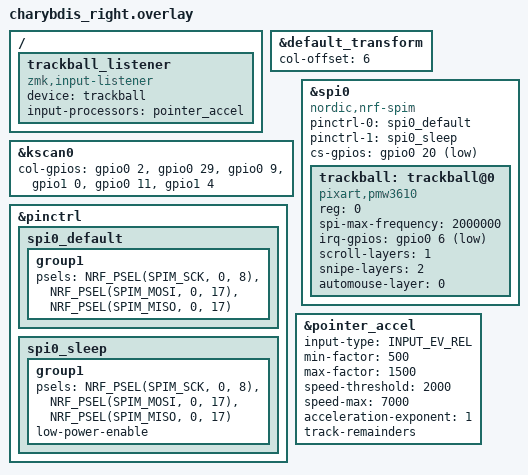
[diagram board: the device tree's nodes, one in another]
/*
 * Copyright (c) 2020 ZMK Contributors
 *
 * SPDX-License-Identifier: MIT
 */
 
#include "charybdis.dtsi"
#include <input/processors.dtsi>
#include <behaviors/input_gestures_accel.dtsi>


&default_transform {
    col-offset = <6>;
};

&kscan0 {
	col-gpios
		= <&gpio0 2 (GPIO_ACTIVE_HIGH | GPIO_PULL_DOWN)>
        , <&gpio0 29 (GPIO_ACTIVE_HIGH | GPIO_PULL_DOWN)>
        , <&gpio0 9 (GPIO_ACTIVE_HIGH | GPIO_PULL_DOWN)>
        , <&gpio1 0  (GPIO_ACTIVE_HIGH | GPIO_PULL_DOWN)>
        , <&gpio0 11 (GPIO_ACTIVE_HIGH | GPIO_PULL_DOWN)>
        , <&gpio1 4  (GPIO_ACTIVE_HIGH | GPIO_PULL_DOWN)>
		;
};

// trackball bus
&pinctrl {
    spi0_default: spi0_default {
        group1 {
            psels = <NRF_PSEL(SPIM_SCK, 0, 8)>,
                <NRF_PSEL(SPIM_MOSI, 0, 17)>,
                <NRF_PSEL(SPIM_MISO, 0, 17)>;
        };
    };

    spi0_sleep: spi0_sleep {
        group1 {
            psels = <NRF_PSEL(SPIM_SCK, 0, 8)>,
                <NRF_PSEL(SPIM_MOSI, 0, 17)>,
                <NRF_PSEL(SPIM_MISO, 0, 17)>;
            low-power-enable;
        };
    };
};

&spi0 {
    status = "okay";
    compatible = "nordic,nrf-spim";
    pinctrl-0 = <&spi0_default>;
    pinctrl-1 = <&spi0_sleep>;
    pinctrl-names = "default", "sleep";
    cs-gpios = <&gpio0 20 GPIO_ACTIVE_LOW>;

    trackball: trackball@0 {
        status = "okay";
        compatible = "pixart,pmw3610";
        reg = <0>;
        spi-max-frequency = <2000000>;
        irq-gpios = <&gpio0 6 (GPIO_ACTIVE_LOW | GPIO_PULL_UP)>;
        scroll-layers = <1>;
        snipe-layers = <2>;
        automouse-layer = <0>;
    };
};

&pointer_accel {
    input-type = <INPUT_EV_REL>;
    min-factor = <500>;        // 0.5x for fine control
    max-factor = <1500>;       // 1.5x maximum
    speed-threshold = <2000>;  // High threshold for stability
    speed-max = <7000>;          // 6000 counts/sec for max accel
    acceleration-exponent = <1>; // Linear response
    track-remainders;          // Track fractional movements
};

/ {
    trackball_listener {
        compatible = "zmk,input-listener";
        device = <&trackball>;
        status = "okay";
        input-processors = <
            &pointer_accel      // Acceleration processor
        >;
    };
};
